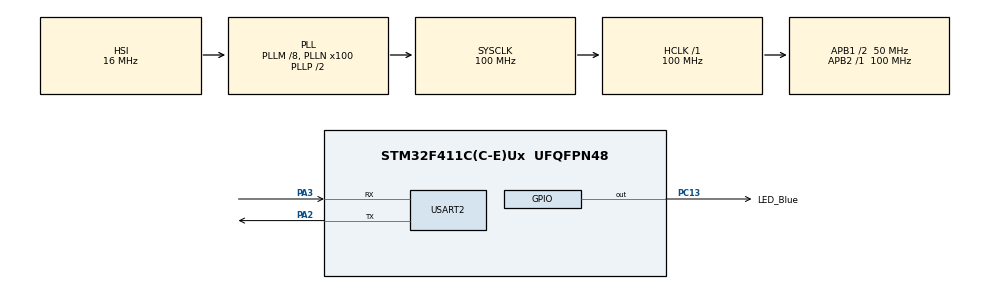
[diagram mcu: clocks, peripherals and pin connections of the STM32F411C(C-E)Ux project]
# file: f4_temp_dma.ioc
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ADC1.Channel-1\#ChannelRegularConversion=ADC_CHANNEL_TEMPSENSOR
ADC1.ContinuousConvMode=ENABLE
ADC1.DMAContinuousRequests=ENABLE
ADC1.EOCSelection=ADC_EOC_SEQ_CONV
ADC1.NbrOfConversionFlag=1
ADC1.Rank-1\#ChannelRegularConversion=1
ADC1.SamplingTime-1\#ChannelRegularConversion=ADC_SAMPLETIME_3CYCLES
ADC1.master=1
Dma.ADC1.0.Direction=DMA_PERIPH_TO_MEMORY
Dma.ADC1.0.FIFOMode=DMA_FIFOMODE_DISABLE
Dma.ADC1.0.Instance=DMA2_Stream0
Dma.ADC1.0.MemDataAlignment=DMA_MDATAALIGN_HALFWORD
Dma.ADC1.0.MemInc=DMA_MINC_ENABLE
Dma.ADC1.0.Mode=DMA_CIRCULAR
Dma.ADC1.0.PeriphDataAlignment=DMA_PDATAALIGN_HALFWORD
Dma.ADC1.0.PeriphInc=DMA_PINC_DISABLE
Dma.ADC1.0.Priority=DMA_PRIORITY_LOW
Dma.Request0=ADC1
Mcu.Family=STM32F4
Mcu.Name=STM32F411C(C-E)Ux
Mcu.Package=UFQFPN48
NVIC.ADC_IRQn=true\:0\:0\:false\:false\:true\:true\:true
NVIC.DMA2_Stream0_IRQn=true\:0\:0\:false\:false\:true\:false\:true
NVIC.PriorityGroup=NVIC_PRIORITYGROUP_4
PA2.Mode=Asynchronous
PA2.Signal=USART2_TX
PA3.Mode=Asynchronous
PA3.Signal=USART2_RX
PC13-ANTI_TAMP.GPIO_Label=LED_Blue
PC13-ANTI_TAMP.GPIO_ModeDefaultOutputPP=GPIO_MODE_OUTPUT_OD
PC13-ANTI_TAMP.GPIO_PuPd=GPIO_NOPULL
PC13-ANTI_TAMP.PinState=GPIO_PIN_SET
PC13-ANTI_TAMP.Signal=GPIO_Output
ProjectManager.HeapSize=0x200
ProjectManager.StackSize=0x400
ProjectManager.TargetToolchain=Makefile
RCC.48MHZClocksFreq_Value=50000000
RCC.AHBFreq_Value=100000000
RCC.APB1CLKDivider=RCC_HCLK_DIV2
RCC.APB1Freq_Value=50000000
RCC.APB1TimFreq_Value=100000000
RCC.APB2Freq_Value=100000000
RCC.APB2TimFreq_Value=100000000
RCC.CortexFreq_Value=100000000
RCC.HCLKFreq_Value=100000000
RCC.HSE_VALUE=25000000
RCC.HSI_VALUE=16000000
RCC.LSE_VALUE=32768
RCC.PLLM=8
RCC.PLLN=100
RCC.SYSCLKFreq_VALUE=100000000
RCC.SYSCLKSource=RCC_SYSCLKSOURCE_PLLCLK
RCC.VCOOutputFreq_Value=200000000
USART2.VirtualMode=VM_ASYNC
VP_ADC1_TempSens_Input.Mode=IN-TempSens
board=custom

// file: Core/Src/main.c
/* USER CODE BEGIN Header */
/**
  ******************************************************************************
  * @file           : main.c
  * @brief          : Main program body
  ******************************************************************************
  * @attention
  *
  * <h2><center>&copy; Copyright (c) 2021 STMicroelectronics.
  * All rights reserved.</center></h2>
  *
  * This software component is licensed by ST under BSD 3-Clause license,
  * the "License"; You may not use this file except in compliance with the
  * License. You may obtain a copy of the License at:
  *                        opensource.org/licenses/BSD-3-Clause
  *
  ******************************************************************************
  */
/* USER CODE END Header */
#include "main.h"

/* USER CODE BEGIN Includes */
#include <stdio.h>
#include <stdlib.h>
#include <string.h>

/* USER CODE END Includes */

ADC_HandleTypeDef hadc1;
DMA_HandleTypeDef hdma_adc1;

UART_HandleTypeDef huart2;

/* USER CODE BEGIN PV */
uint16_t ADC_raw = 0;
char output_buffer[256] = {0};

/* USER CODE END PV */

void SystemClock_Config(void);
static void MX_ADC1_Init(void);
static void MX_USART2_UART_Init(void);

int main(void)
{

  /* MCU Configuration--------------------------------------------------------*/

  /* Reset of all peripherals, Initializes the Flash interface and the Systick. */
  HAL_Init();

  /* Configure the system clock */
  SystemClock_Config();

  /* Initialize all configured peripherals */
  MX_DMA_Init();
  MX_ADC1_Init();
  MX_GPIO_Init();
  MX_USART2_UART_Init();
  /* USER CODE BEGIN 2 */
  HAL_ADC_Start_DMA(&hadc1, (uint32_t*)&ADC_raw, 1);

  /* USER CODE END 2 */

  /* Infinite loop */
  /* USER CODE BEGIN WHILE */
  HAL_GPIO_WritePin(LED_Blue_GPIO_Port, LED_Blue_Pin, GPIO_PIN_SET);
  char* initString =  "system initialized\r\n";
  HAL_UART_Transmit(&huart2, (uint8_t*)initString, sizeof(initString), HAL_MAX_DELAY);
  while (1)
  {
      sprintf(output_buffer, "%d C\r\n", ADC_raw);
      HAL_UART_Transmit(&huart2, (uint8_t*)output_buffer, sizeof(output_buffer), HAL_MAX_DELAY);
      memset(output_buffer, 0, 256);
      HAL_ADC_Start(&hadc1);
      HAL_Delay(1000);
      HAL_GPIO_TogglePin(LED_Blue_GPIO_Port, LED_Blue_Pin);
    /* USER CODE END WHILE */

  }
}

void SystemClock_Config(void)
{
  RCC_OscInitTypeDef RCC_OscInitStruct = {0};
  RCC_ClkInitTypeDef RCC_ClkInitStruct = {0};

  /** Configure the main internal regulator output voltage
  */
  __HAL_RCC_PWR_CLK_ENABLE();
  __HAL_PWR_VOLTAGESCALING_CONFIG(PWR_REGULATOR_VOLTAGE_SCALE1);
  /** Initializes the RCC Oscillators according to the specified parameters
  * in the RCC_OscInitTypeDef structure.
  */
  RCC_OscInitStruct.OscillatorType = RCC_OSCILLATORTYPE_HSI;
  RCC_OscInitStruct.HSIState = RCC_HSI_ON;
  RCC_OscInitStruct.HSICalibrationValue = RCC_HSICALIBRATION_DEFAULT;
  RCC_OscInitStruct.PLL.PLLState = RCC_PLL_ON;
  RCC_OscInitStruct.PLL.PLLSource = RCC_PLLSOURCE_HSI;
  RCC_OscInitStruct.PLL.PLLM = 8;
  RCC_OscInitStruct.PLL.PLLN = 100;
  RCC_OscInitStruct.PLL.PLLP = RCC_PLLP_DIV2;
  RCC_OscInitStruct.PLL.PLLQ = 4;
  if (HAL_RCC_OscConfig(&RCC_OscInitStruct) != HAL_OK)
  {
    Error_Handler();
  }
  /** Initializes the CPU, AHB and APB buses clocks
  */
  RCC_ClkInitStruct.ClockType = RCC_CLOCKTYPE_HCLK|RCC_CLOCKTYPE_SYSCLK
                              |RCC_CLOCKTYPE_PCLK1|RCC_CLOCKTYPE_PCLK2;
  RCC_ClkInitStruct.SYSCLKSource = RCC_SYSCLKSOURCE_PLLCLK;
  RCC_ClkInitStruct.AHBCLKDivider = RCC_SYSCLK_DIV1;
  RCC_ClkInitStruct.APB1CLKDivider = RCC_HCLK_DIV2;
  RCC_ClkInitStruct.APB2CLKDivider = RCC_HCLK_DIV1;

  if (HAL_RCC_ClockConfig(&RCC_ClkInitStruct, FLASH_LATENCY_3) != HAL_OK)
  {
    Error_Handler();
  }
}

static void MX_ADC1_Init(void)
{

  ADC_ChannelConfTypeDef sConfig = {0};

  /** Configure the global features of the ADC (Clock, Resolution, Data Alignment and number of conversion)
  */
  hadc1.Instance = ADC1;
  hadc1.Init.ClockPrescaler = ADC_CLOCK_SYNC_PCLK_DIV4;
  hadc1.Init.Resolution = ADC_RESOLUTION_12B;
  hadc1.Init.ScanConvMode = DISABLE;
  hadc1.Init.ContinuousConvMode = ENABLE;
  hadc1.Init.DiscontinuousConvMode = DISABLE;
  hadc1.Init.ExternalTrigConvEdge = ADC_EXTERNALTRIGCONVEDGE_NONE;
  hadc1.Init.ExternalTrigConv = ADC_SOFTWARE_START;
  hadc1.Init.DataAlign = ADC_DATAALIGN_RIGHT;
  hadc1.Init.NbrOfConversion = 1;
  hadc1.Init.DMAContinuousRequests = ENABLE;
  hadc1.Init.EOCSelection = ADC_EOC_SEQ_CONV;
  if (HAL_ADC_Init(&hadc1) != HAL_OK)
  {
    Error_Handler();
  }
  /** Configure for the selected ADC regular channel its corresponding rank in the sequencer and its sample time.
  */
  sConfig.Channel = ADC_CHANNEL_TEMPSENSOR;
  sConfig.Rank = 1;
  sConfig.SamplingTime = ADC_SAMPLETIME_3CYCLES;
  if (HAL_ADC_ConfigChannel(&hadc1, &sConfig) != HAL_OK)
  {
    Error_Handler();
  }

}

static void MX_USART2_UART_Init(void)
{

  huart2.Instance = USART2;
  huart2.Init.BaudRate = 115200;
  huart2.Init.WordLength = UART_WORDLENGTH_8B;
  huart2.Init.StopBits = UART_STOPBITS_1;
  huart2.Init.Parity = UART_PARITY_NONE;
  huart2.Init.Mode = UART_MODE_TX_RX;
  huart2.Init.HwFlowCtl = UART_HWCONTROL_NONE;
  huart2.Init.OverSampling = UART_OVERSAMPLING_16;
  if (HAL_UART_Init(&huart2) != HAL_OK)
  {
    Error_Handler();
  }

}

void MX_DMA_Init(void)
{

  /* DMA controller clock enable */
  __HAL_RCC_DMA2_CLK_ENABLE();

  /* DMA interrupt init */
  /* DMA2_Stream0_IRQn interrupt configuration */
  HAL_NVIC_SetPriority(DMA2_Stream0_IRQn, 0, 0);
  HAL_NVIC_EnableIRQ(DMA2_Stream0_IRQn);

}

void MX_GPIO_Init(void)
{
  GPIO_InitTypeDef GPIO_InitStruct = {0};

  /* GPIO Ports Clock Enable */
  __HAL_RCC_GPIOC_CLK_ENABLE();
  __HAL_RCC_GPIOA_CLK_ENABLE();

  /*Configure GPIO pin Output Level */
  HAL_GPIO_WritePin(LED_Blue_GPIO_Port, LED_Blue_Pin, GPIO_PIN_SET);

  /*Configure GPIO pin : LED_Blue_Pin */
  GPIO_InitStruct.Pin = LED_Blue_Pin;
  GPIO_InitStruct.Mode = GPIO_MODE_OUTPUT_OD;
  GPIO_InitStruct.Pull = GPIO_NOPULL;
  GPIO_InitStruct.Speed = GPIO_SPEED_FREQ_LOW;
  HAL_GPIO_Init(LED_Blue_GPIO_Port, &GPIO_InitStruct);

}

void Error_Handler(void)
{
  __disable_irq();
  while (1)
  {
  }
}

/************************ (C) COPYRIGHT STMicroelectronics *****END OF FILE****/
